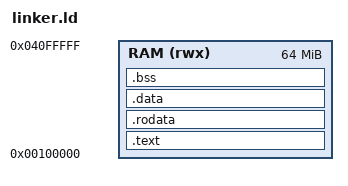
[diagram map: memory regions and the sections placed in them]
ENTRY(_start)

MEMORY
{
    RAM (rwx) : ORIGIN = 0x00100000, LENGTH = 64M
}

SECTIONS
{
    .text :
    {
        *(.text*)
    } > RAM

    .rodata :
    {
        *(.rodata*)
    } > RAM

    .data :
    {
        *(.data*)
    } > RAM

    .bss :
    {
        __bss_start = .;
        *(.bss*)
        *(COMMON)
        __bss_end = .;
    } > RAM
}
